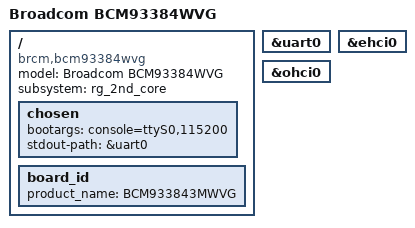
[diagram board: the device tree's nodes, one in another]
/dts-v1/;

/include/ "bcm3384_zephyr.dtsi"

/ {
	compatible = "brcm,bcm93384wvg", "brcm,bcm3384";
	model = "Broadcom BCM93384WVG";
	subsystem = "rg_2nd_core";

	chosen {
		bootargs = "console=ttyS0,115200";
		stdout-path = &uart0;
	};
	board_id {
		product_name = "BCM933843MWVG";
	};
};

&uart0 {
	status = "okay";
};

&ehci0 {
	status = "okay";
};

&ohci0 {
	status = "okay";
};

/include/ "bcm33843mwvg_mgw_zephyr.dtsi"
